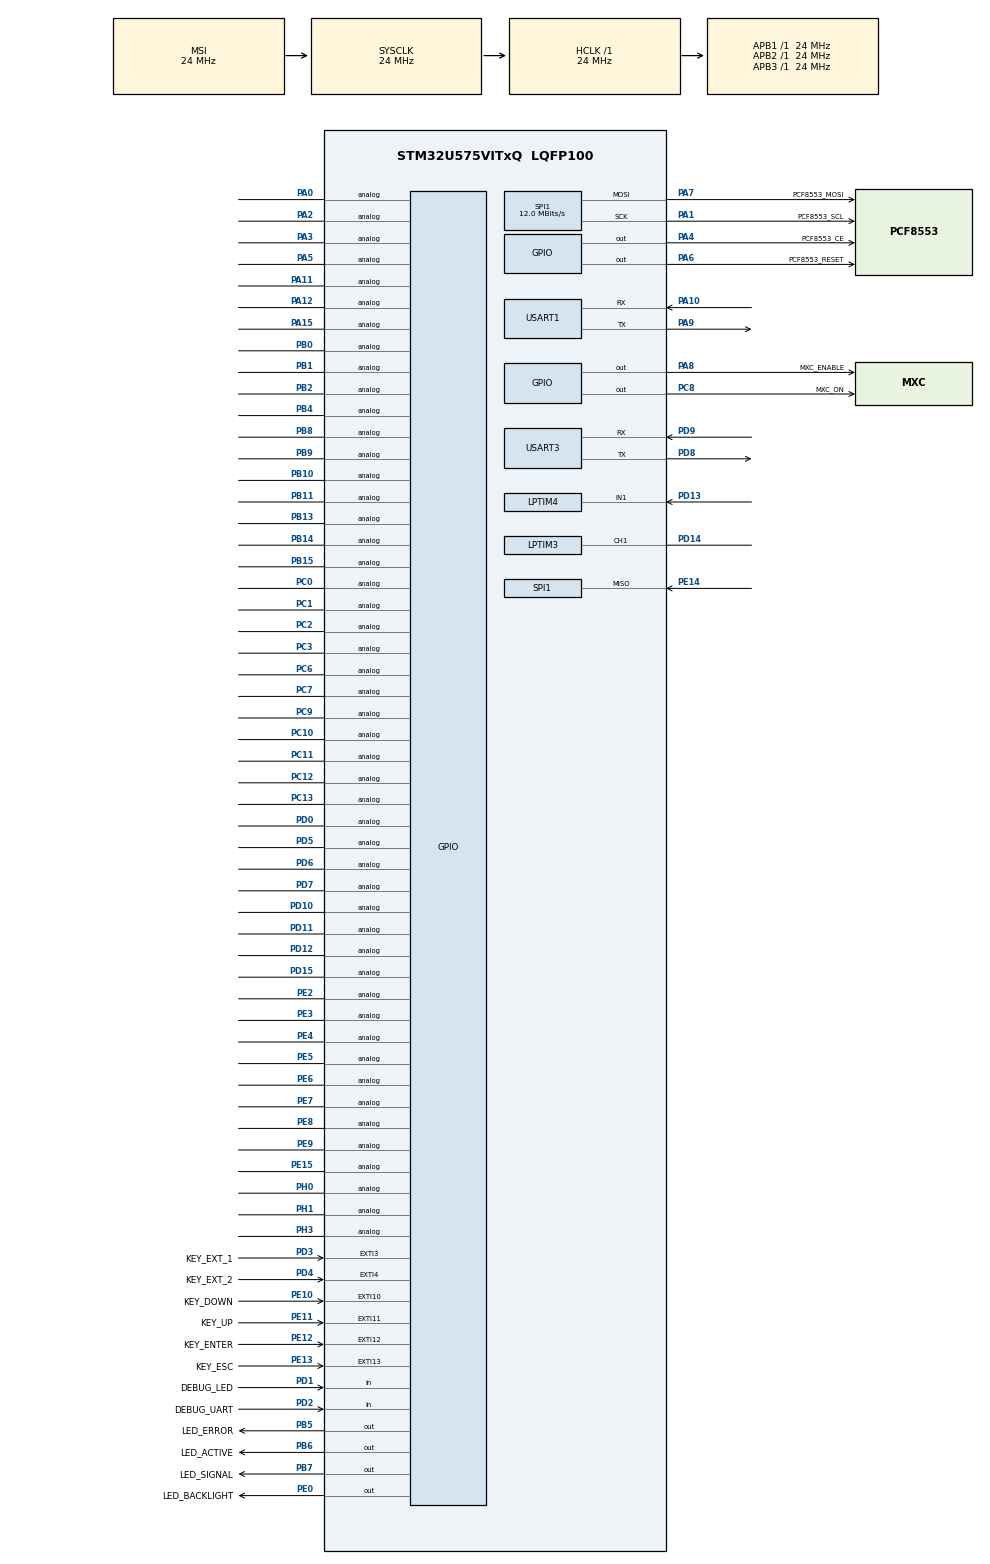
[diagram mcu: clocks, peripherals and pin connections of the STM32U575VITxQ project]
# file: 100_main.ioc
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CORTEX_M33_NS.AccessPermission-Cortex_Memory_Protection_Unit_Region0_Settings=MPU_REGION_PRIV_RO
CORTEX_M33_NS.AllocateAttribute-Cortex_Memory_Protection_Unit_Region0_Settings=MPU_R_ALLOCATE
CORTEX_M33_NS.AllocateAttribute-Cortex_Memory_Protection_Unit_Region1_Settings=MPU_RW_ALLOCATE
CORTEX_M33_NS.AllocateAttribute-Cortex_Memory_Protection_Unit_Region2_Settings=MPU_RW_ALLOCATE
CORTEX_M33_NS.AllocateAttribute0=MPU_RW_ALLOCATE
CORTEX_M33_NS.AllocateAttribute1=MPU_R_ALLOCATE
CORTEX_M33_NS.AllocateAttribute2=MPU_RW_ALLOCATE
CORTEX_M33_NS.Attributes0=MPU_ATTRIBUTES_NUMBER0
CORTEX_M33_NS.Attributes1=MPU_ATTRIBUTES_NUMBER1
CORTEX_M33_NS.Attributes2=MPU_ATTRIBUTES_NUMBER2
CORTEX_M33_NS.AttributesIndex-Cortex_Memory_Protection_Unit_Region0_Settings=MPU_ATTRIBUTES_NUMBER1
CORTEX_M33_NS.AttributesIndex-Cortex_Memory_Protection_Unit_Region1_Settings=MPU_ATTRIBUTES_NUMBER2
CORTEX_M33_NS.AttributesIndex-Cortex_Memory_Protection_Unit_Region2_Settings=MPU_ATTRIBUTES_NUMBER0
CORTEX_M33_NS.BaseAddress-Cortex_Memory_Protection_Unit_Region0_Settings=0x08000000
CORTEX_M33_NS.BaseAddress-Cortex_Memory_Protection_Unit_Region1_Settings=0x20000000
CORTEX_M33_NS.BaseAddress-Cortex_Memory_Protection_Unit_Region2_Settings=0x40036400
CORTEX_M33_NS.CacheableAttribute-Cortex_Memory_Protection_Unit_Region0_Settings=MPU_WRITE_THROUGH
CORTEX_M33_NS.CacheableAttribute-Cortex_Memory_Protection_Unit_Region1_Settings=MPU_WRITE_BACK
CORTEX_M33_NS.CacheableAttribute-Cortex_Memory_Protection_Unit_Region2_Settings=MPU_WRITE_BACK
CORTEX_M33_NS.CacheableAttribute0=MPU_WRITE_BACK
CORTEX_M33_NS.CacheableAttribute1=MPU_WRITE_THROUGH
CORTEX_M33_NS.CacheableAttribute2=MPU_WRITE_BACK
CORTEX_M33_NS.DisableExec-Cortex_Memory_Protection_Unit_Region2_Settings=MPU_INSTRUCTION_ACCESS_DISABLE
CORTEX_M33_NS.Enable-Cortex_Memory_Protection_Unit_Region0_Settings=MPU_REGION_ENABLE
CORTEX_M33_NS.Enable-Cortex_Memory_Protection_Unit_Region1_Settings=MPU_REGION_ENABLE
CORTEX_M33_NS.Enable-Cortex_Memory_Protection_Unit_Region2_Settings=MPU_REGION_ENABLE
CORTEX_M33_NS.LimitAddress-Cortex_Memory_Protection_Unit_Region0_Settings=0x080FFFFF
CORTEX_M33_NS.LimitAddress-Cortex_Memory_Protection_Unit_Region1_Settings=0x200BFFFF
CORTEX_M33_NS.LimitAddress-Cortex_Memory_Protection_Unit_Region2_Settings=0x40036BFF
CORTEX_M33_NS.MPU_Control=MPU_PRIVILEGED_DEFAULT
CORTEX_M33_NS.Memorytype0=MPU_CACHEABLE
CORTEX_M33_NS.Memorytype1=MPU_CACHEABLE
CORTEX_M33_NS.Memorytype2=MPU_CACHEABLE
CORTEX_M33_NS.Number-Cortex_Memory_Protection_Unit_Region1_Settings=MPU_REGION_NUMBER1
CORTEX_M33_NS.Number-Cortex_Memory_Protection_Unit_Region2_Settings=MPU_REGION_NUMBER2
CORTEX_M33_NS.TransientAttribute0=MPU_TRANSIENT
CORTEX_M33_NS.TransientAttribute1=MPU_TRANSIENT
CORTEX_M33_NS.TransientAttribute2=MPU_TRANSIENT
CORTEX_M33_NS.userName=CORTEX_M33
FLASH.B1_BLOCK_active=true
FLASH.B1_endPage=127
FLASH.OB_Boot_Configuration_active_NS0=true
FLASH.OB_NSBOOTADD0_Address=0x08000000
LPTIM1.Capture_Compare_Selection_1=UI_output
LPTIM1.ClockPrescaler=LPTIM_PRESCALER_DIV16
LPTIM1.OCPulse_1=65535
LPTIM4.ULPClockPolarity=LPTIM_CLOCKPOLARITY_FALLING
Mcu.Family=STM32U5
Mcu.Name=STM32U575VITxQ
Mcu.Package=LQFP100
NVIC.EXTI10_IRQn=true\:0\:0\:false\:false\:true\:false\:true\:true\:true
NVIC.EXTI11_IRQn=true\:0\:0\:false\:false\:true\:false\:true\:true\:true
NVIC.EXTI12_IRQn=true\:0\:0\:false\:false\:true\:false\:true\:true\:true
NVIC.EXTI13_IRQn=true\:0\:0\:false\:false\:true\:false\:true\:true\:true
NVIC.EXTI3_IRQn=true\:0\:0\:false\:false\:true\:false\:true\:true\:true
NVIC.EXTI4_IRQn=true\:0\:0\:false\:false\:true\:false\:true\:true\:true
NVIC.LPTIM1_IRQn=true\:0\:0\:false\:false\:true\:false\:true\:true\:true
NVIC.LPTIM3_IRQn=true\:0\:0\:false\:false\:true\:false\:true\:true\:true
NVIC.PriorityGroup=NVIC_PRIORITYGROUP_4
NVIC.TIM6_IRQn=true\:15\:0\:false\:false\:true\:false\:false\:true\:true
NVIC.TimeBase=TIM6_IRQn
NVIC.TimeBaseIP=TIM6
NVIC.USART3_IRQn=true\:0\:0\:false\:false\:true\:false\:true\:true\:true
PA0.Signal=GPIO_Analog
PA1.GPIO_Label=PCF8553_SCL
PA1.Mode=Full_Duplex_Master
PA1.Signal=SPI1_SCK
PA10.Mode=Asynchronous
PA10.Signal=USART1_RX
PA11.Signal=GPIO_Analog
PA12.Signal=GPIO_Analog
PA13\ (JTMS/SWDIO).Mode=Trace_Asynchronous_SW
PA13\ (JTMS/SWDIO).Signal=DEBUG_JTMS-SWDIO
PA14\ (JTCK/SWCLK).Mode=Trace_Asynchronous_SW
PA14\ (JTCK/SWCLK).Signal=DEBUG_JTCK-SWCLK
PA15\ (JTDI).Signal=GPIO_Analog
PA2.Signal=GPIO_Analog
PA3.Signal=GPIO_Analog
PA4.GPIO_Label=PCF8553_CE
PA4.Signal=GPIO_Output
PA5.Signal=GPIO_Analog
PA6.GPIO_Label=PCF8553_RESET
PA6.Signal=GPIO_Output
PA7.GPIO_Label=PCF8553_MOSI
PA7.Mode=Full_Duplex_Master
PA7.Signal=SPI1_MOSI
PA8.GPIO_Label=MXC_ENABLE
PA8.Signal=GPIO_Output
PA9.Mode=Asynchronous
PA9.Signal=USART1_TX
PB0.Signal=GPIO_Analog
PB1.Signal=GPIO_Analog
PB10.Signal=GPIO_Analog
PB11.Signal=GPIO_Analog
PB13.Signal=GPIO_Analog
PB14.Signal=GPIO_Analog
PB15.Signal=GPIO_Analog
PB2.Signal=GPIO_Analog
PB3\ (JTDO/TRACESWO).Mode=Trace_Asynchronous_SW
PB3\ (JTDO/TRACESWO).Signal=DEBUG_JTDO-SWO
PB4\ (NJTRST).Signal=GPIO_Analog
PB5.GPIO_Label=LED_ERROR
PB5.Signal=GPIO_Output
PB6.GPIO_Label=LED_ACTIVE
PB6.Signal=GPIO_Output
PB7.GPIO_Label=LED_SIGNAL
PB7.Signal=GPIO_Output
PB8.Signal=GPIO_Analog
PB9.Signal=GPIO_Analog
PC0.Signal=GPIO_Analog
PC1.Signal=GPIO_Analog
PC10.Signal=GPIO_Analog
PC11.Signal=GPIO_Analog
PC12.Signal=GPIO_Analog
PC13.Signal=GPIO_Analog
PC14-OSC32_IN\ (PC14).Mode=LSE-External-Oscillator
PC14-OSC32_IN\ (PC14).Signal=RCC_OSC32_IN
PC15-OSC32_OUT\ (PC15).Mode=LSE-External-Oscillator
PC15-OSC32_OUT\ (PC15).Signal=RCC_OSC32_OUT
PC2.Signal=GPIO_Analog
PC3.Signal=GPIO_Analog
PC6.Signal=GPIO_Analog
PC7.Signal=GPIO_Analog
PC8.GPIO_Label=MXC_ON
PC8.Signal=GPIO_Output
PC9.Signal=GPIO_Analog
PD0.Signal=GPIO_Analog
PD1.GPIO_Label=DEBUG_LED
PD1.Signal=GPIO_Input
PD10.Signal=GPIO_Analog
PD11.Signal=GPIO_Analog
PD12.Signal=GPIO_Analog
PD13.Mode=Counts_external_clock_standalone_1X_occur1
PD13.Signal=LPTIM4_IN1
PD14.Signal=S_LPTIM3_CH1
PD15.Signal=GPIO_Analog
PD2.GPIO_Label=DEBUG_UART
PD2.Signal=GPIO_Input
PD3.GPIO_Label=KEY_EXT_1
PD3.GPIO_ModeDefaultEXTI=GPIO_MODE_IT_FALLING
PD3.GPIO_PuPd=GPIO_PULLUP
PD3.Signal=GPXTI3
PD4.GPIO_Label=KEY_EXT_2
PD4.GPIO_ModeDefaultEXTI=GPIO_MODE_IT_FALLING
PD4.GPIO_PuPd=GPIO_PULLUP
PD4.Signal=GPXTI4
PD5.Signal=GPIO_Analog
PD6.Signal=GPIO_Analog
PD7.Signal=GPIO_Analog
PD8.Mode=Asynchronous
PD8.Signal=USART3_TX
PD9.Mode=Asynchronous
PD9.Signal=USART3_RX
PE0.GPIO_Label=LED_BACKLIGHT
PE0.Signal=GPIO_Output
PE10.GPIO_Label=KEY_DOWN
PE10.GPIO_ModeDefaultEXTI=GPIO_MODE_IT_RISING_FALLING
PE10.Signal=GPXTI10
PE11.GPIO_Label=KEY_UP
PE11.GPIO_ModeDefaultEXTI=GPIO_MODE_IT_RISING_FALLING
PE11.Signal=GPXTI11
PE12.GPIO_Label=KEY_ENTER
PE12.GPIO_ModeDefaultEXTI=GPIO_MODE_IT_RISING_FALLING
PE12.Signal=GPXTI12
PE13.GPIO_Label=KEY_ESC
PE13.GPIO_ModeDefaultEXTI=GPIO_MODE_IT_RISING_FALLING
PE13.Signal=GPXTI13
PE14.Mode=Full_Duplex_Master
PE14.Signal=SPI1_MISO
PE15.Signal=GPIO_Analog
PE2.Signal=GPIO_Analog
PE3.Signal=GPIO_Analog
PE4.Signal=GPIO_Analog
PE5.Signal=GPIO_Analog
PE6.Signal=GPIO_Analog
PE7.Signal=GPIO_Analog
PE8.Signal=GPIO_Analog
PE9.Signal=GPIO_Analog
PH0-OSC_IN\ (PH0).Signal=GPIO_Analog
PH1-OSC_OUT\ (PH1).Signal=GPIO_Analog
PH3-BOOT0.Signal=GPIO_Analog
PWR.PowerMode=PWR_SMPS_SUPPLY
ProjectManager.HeapSize=0x200
ProjectManager.StackSize=0x400
ProjectManager.TargetToolchain=STM32CubeIDE
RCC.ADCFreq_Value=16000000
RCC.AHBFreq_Value=24000000
RCC.APB1Freq_Value=24000000
RCC.APB1TimFreq_Value=24000000
RCC.APB2Freq_Value=24000000
RCC.APB2TimFreq_Value=24000000
RCC.APB3Freq_Value=24000000
RCC.CortexFreq_Value=24000000
RCC.EPOD_VALUE=24000000
RCC.FLatency=FLASH_LATENCY_1
RCC.HCLKFreq_Value=24000000
RCC.HSE_VALUE=16000000
RCC.HSI48_VALUE=48000000
RCC.HSI_VALUE=16000000
RCC.LPTIM1CLockSelectionVirtual=RCC_LPTIM1CLKSOURCE_LSE
RCC.LPTIM3CLockSelectionVirtual=RCC_LPTIM34CLKSOURCE_LSE
RCC.LSE_Drive_Capability=RCC_LSEDRIVE_HIGH
RCC.LSIDIV_VALUE=32000
RCC.MSIClockRange=RCC_MSIRANGE_1
RCC.MSIKClockRange=RCC_MSIKRANGE_1
RCC.MSI_VALUE=24000000
RCC.RTCClockSelection=RCC_RTCCLKSOURCE_LSE
RCC.SYSCLKFreq_VALUE=24000000
RCC.USART1CLockSelectionVirtual=RCC_USART1CLKSOURCE_SYSCLK
RCC.USBFreq_Value=48000000
RCC.VCOOutputFreq_Value=3096000000
SH.S_LPTIM3_CH1.0=LPTIM3_CH1,InputIO_CH1
SPI1.CalculateBaudRate=12.0 MBits/s
SPI1.DataSize=SPI_DATASIZE_8BIT
SPI1.Direction=SPI_DIRECTION_2LINES
SPI1.Mode=SPI_MODE_MASTER
SPI1.VirtualType=VM_MASTER
THREADX.TX_APP_MEM_POOL_SIZE=65536
THREADX.TX_LOW_POWER=1
USART1.VirtualMode-Asynchronous=VM_ASYNC
USART3.VirtualMode-Asynchronous=VM_ASYNC
VP_FLASH_SIG_Activate_FlashIP.Mode=Activate_FlashIP
VP_ICACHE_VS_ICACHE.Mode=DirectMappedCache
VP_LPBAMQUEUE_VS_QUEUE.Mode=QUEUEMODE
VP_LPBAM_VS_SIG1.Mode=SmartRun
VP_LPBAM_VS_SIG4.Mode=LPDMA1
VP_LPTIM1_VS_CH1.Mode=Channel_1_Active
VP_LPTIM1_VS_LPTIM_counterModeInternalClock.Mode=Counts__internal_clock_event_00
VP_LPTIM1_VS_noIO1.Mode=NoIO_Channel_1_Active
VP_LPTIM3_VS_CH1.Mode=Channel_1_Active
VP_LPTIM3_VS_LPTIM_counterModeInternalClock.Mode=Counts__internal_clock_event_00
VP_MEMORYMAP_VS_MEMORYMAP.Mode=CurAppReg
VP_PWR_VS_DBSignals.Mode=DisableDeadBatterySignals
VP_PWR_VS_LPOM.Mode=PowerOptimisation
VP_PWR_VS_SECSignals.Mode=Security/Privilege
VP_RTC_VS_RTC_Activate.Mode=RTC_Enabled
VP_SYS_VS_tim6.Mode=TIM6
VP_THREADX_VS_RTOSJjThreadXJjCoreJjDefault.Mode=Core_Default
VP_THREADX_VS_RTOSJjThreadXJjLow_Power_Support.Mode=Low_Power_Support
board=custom

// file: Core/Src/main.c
/* USER CODE BEGIN Header */
/**
  ******************************************************************************
  * @file           : main.c
  * @brief          : Main program body
  ******************************************************************************
  * @attention
  *
  * Copyright (c) 2024 STMicroelectronics.
  * All rights reserved.
  *
  * This software is licensed under terms that can be found in the LICENSE file
  * in the root directory of this software component.
  * If no LICENSE file comes with this software, it is provided AS-IS.
  *
  ******************************************************************************
  */
/* USER CODE END Header */
#include "app_threadx.h"
#include "main.h"
#include "flash.h"
#include "icache.h"
#include "lptim.h"
#include "rtc.h"
#include "spi.h"
#include "usart.h"
#include "gpio.h"

/* USER CODE BEGIN Includes */
#include "fm_debug.h"
#include "fm_init.h"
/* USER CODE END Includes */

void SystemClock_Config(void);
static void SystemPower_Config(void);
static void MPU_Config(void);

int main(void)
{

  /* MCU Configuration--------------------------------------------------------*/

  /* MPU Configuration--------------------------------------------------------*/
  MPU_Config();

  /* Reset of all peripherals, Initializes the Flash interface and the Systick. */
  HAL_Init();

  /* Configure the System Power */
  SystemPower_Config();

  /* Configure the system clock */
  SystemClock_Config();

  /* Initialize all configured peripherals */
  MX_GPIO_Init();
  MX_SPI1_Init();
  MX_ICACHE_Init();
  MX_LPTIM1_Init();
  MX_LPTIM4_Init();
  MX_RTC_Init();
  MX_USART1_UART_Init();
  MX_FLASH_Init();
  MX_LPTIM3_Init();
  MX_USART3_UART_Init();
  /* USER CODE BEGIN 2 */
  // Se resetea el PCF8553
  FM_INIT_Init();

  HAL_GPIO_WritePin(MXC_ENABLE_GPIO_Port, MXC_ENABLE_Pin, GPIO_PIN_SET);
  HAL_GPIO_WritePin(MXC_ENABLE_GPIO_Port, MXC_ENABLE_Pin, GPIO_PIN_RESET);

  /* USER CODE END 2 */

  MX_ThreadX_Init();

  /* We should never get here as control is now taken by the scheduler */

  /* Infinite loop */
  while (1)
  {

  }
}

void SystemClock_Config(void)
{
  RCC_OscInitTypeDef RCC_OscInitStruct = {0};
  RCC_ClkInitTypeDef RCC_ClkInitStruct = {0};

  /** Configure the main internal regulator output voltage
  */
  if (HAL_PWREx_ControlVoltageScaling(PWR_REGULATOR_VOLTAGE_SCALE4) != HAL_OK)
  {
    Error_Handler();
  }

  /** Configure LSE Drive Capability
  */
  HAL_PWR_EnableBkUpAccess();
  __HAL_RCC_LSEDRIVE_CONFIG(RCC_LSEDRIVE_HIGH);

  /** Initializes the CPU, AHB and APB buses clocks
  */
  RCC_OscInitStruct.OscillatorType = RCC_OSCILLATORTYPE_LSE|RCC_OSCILLATORTYPE_MSI;
  RCC_OscInitStruct.LSEState = RCC_LSE_ON;
  RCC_OscInitStruct.MSIState = RCC_MSI_ON;
  RCC_OscInitStruct.MSICalibrationValue = RCC_MSICALIBRATION_DEFAULT;
  RCC_OscInitStruct.MSIClockRange = RCC_MSIRANGE_1;
  RCC_OscInitStruct.PLL.PLLState = RCC_PLL_NONE;
  if (HAL_RCC_OscConfig(&RCC_OscInitStruct) != HAL_OK)
  {
    Error_Handler();
  }

  /** Initializes the CPU, AHB and APB buses clocks
  */
  RCC_ClkInitStruct.ClockType = RCC_CLOCKTYPE_HCLK|RCC_CLOCKTYPE_SYSCLK
                              |RCC_CLOCKTYPE_PCLK1|RCC_CLOCKTYPE_PCLK2
                              |RCC_CLOCKTYPE_PCLK3;
  RCC_ClkInitStruct.SYSCLKSource = RCC_SYSCLKSOURCE_MSI;
  RCC_ClkInitStruct.AHBCLKDivider = RCC_SYSCLK_DIV1;
  RCC_ClkInitStruct.APB1CLKDivider = RCC_HCLK_DIV1;
  RCC_ClkInitStruct.APB2CLKDivider = RCC_HCLK_DIV1;
  RCC_ClkInitStruct.APB3CLKDivider = RCC_HCLK_DIV1;

  if (HAL_RCC_ClockConfig(&RCC_ClkInitStruct, FLASH_LATENCY_1) != HAL_OK)
  {
    Error_Handler();
  }
}

/**
  * @brief Power Configuration
  * @retval None
  */
static void SystemPower_Config(void)
{

  /*
   * Disable the internal Pull-Up in Dead Battery pins of UCPD peripheral
   */
  HAL_PWREx_DisableUCPDDeadBattery();

  /*
   * Switch to SMPS regulator instead of LDO
   */
  if (HAL_PWREx_ConfigSupply(PWR_SMPS_SUPPLY) != HAL_OK)
  {
    Error_Handler();
  }
}

 /* MPU Configuration */

static void MPU_Config(void)
{
  MPU_Region_InitTypeDef MPU_InitStruct = {0};
  MPU_Attributes_InitTypeDef MPU_AttributesInit = {0};

  /* Disables the MPU */
  HAL_MPU_Disable();

  /** Initializes and configures the Region 0 and the memory to be protected
  */
  MPU_InitStruct.Enable = MPU_REGION_ENABLE;
  MPU_InitStruct.Number = MPU_REGION_NUMBER0;
  MPU_InitStruct.BaseAddress = 0x08000000;
  MPU_InitStruct.LimitAddress = 0x080FFFFF;
  MPU_InitStruct.AttributesIndex = MPU_ATTRIBUTES_NUMBER1;
  MPU_InitStruct.AccessPermission = MPU_REGION_PRIV_RO;
  MPU_InitStruct.DisableExec = MPU_INSTRUCTION_ACCESS_ENABLE;
  MPU_InitStruct.IsShareable = MPU_ACCESS_NOT_SHAREABLE;

  HAL_MPU_ConfigRegion(&MPU_InitStruct);

  /** Initializes and configures the Region 1 and the memory to be protected
  */
  MPU_InitStruct.Number = MPU_REGION_NUMBER1;
  MPU_InitStruct.BaseAddress = 0x20000000;
  MPU_InitStruct.LimitAddress = 0x200BFFFF;
  MPU_InitStruct.AttributesIndex = MPU_ATTRIBUTES_NUMBER2;
  MPU_InitStruct.AccessPermission = MPU_REGION_PRIV_RW;

  HAL_MPU_ConfigRegion(&MPU_InitStruct);

  /** Initializes and configures the Region 2 and the memory to be protected
  */
  MPU_InitStruct.Number = MPU_REGION_NUMBER2;
  MPU_InitStruct.BaseAddress = 0x40036400;
  MPU_InitStruct.LimitAddress = 0x40036BFF;
  MPU_InitStruct.AttributesIndex = MPU_ATTRIBUTES_NUMBER0;
  MPU_InitStruct.DisableExec = MPU_INSTRUCTION_ACCESS_DISABLE;

  HAL_MPU_ConfigRegion(&MPU_InitStruct);

  /** Initializes and configures the Attribute 0 and the memory to be protected
  */
  MPU_AttributesInit.Number = MPU_ATTRIBUTES_NUMBER0;
  MPU_AttributesInit.Attributes = INNER_OUTER(MPU_WRITE_BACK|MPU_TRANSIENT
                              |MPU_RW_ALLOCATE);

  HAL_MPU_ConfigMemoryAttributes(&MPU_AttributesInit);

  /** Initializes and configures the Attribute 1 and the memory to be protected
  */
  MPU_AttributesInit.Number = MPU_ATTRIBUTES_NUMBER1;
  MPU_AttributesInit.Attributes = INNER_OUTER(MPU_WRITE_THROUGH|MPU_TRANSIENT
                              |MPU_R_ALLOCATE);

  HAL_MPU_ConfigMemoryAttributes(&MPU_AttributesInit);

  /** Initializes and configures the Attribute 2 and the memory to be protected
  */
  MPU_AttributesInit.Number = MPU_ATTRIBUTES_NUMBER2;
  MPU_AttributesInit.Attributes = INNER_OUTER(MPU_WRITE_BACK|MPU_TRANSIENT
                              |MPU_RW_ALLOCATE);

  HAL_MPU_ConfigMemoryAttributes(&MPU_AttributesInit);
  /* Enables the MPU */
  HAL_MPU_Enable(MPU_PRIVILEGED_DEFAULT);

}

void HAL_TIM_PeriodElapsedCallback(TIM_HandleTypeDef *htim)
{
  if (htim->Instance == TIM6)
  {
    HAL_IncTick();
  }
}

void Error_Handler(void)
{
  __disable_irq();
  while (1)
  {
  }
}
